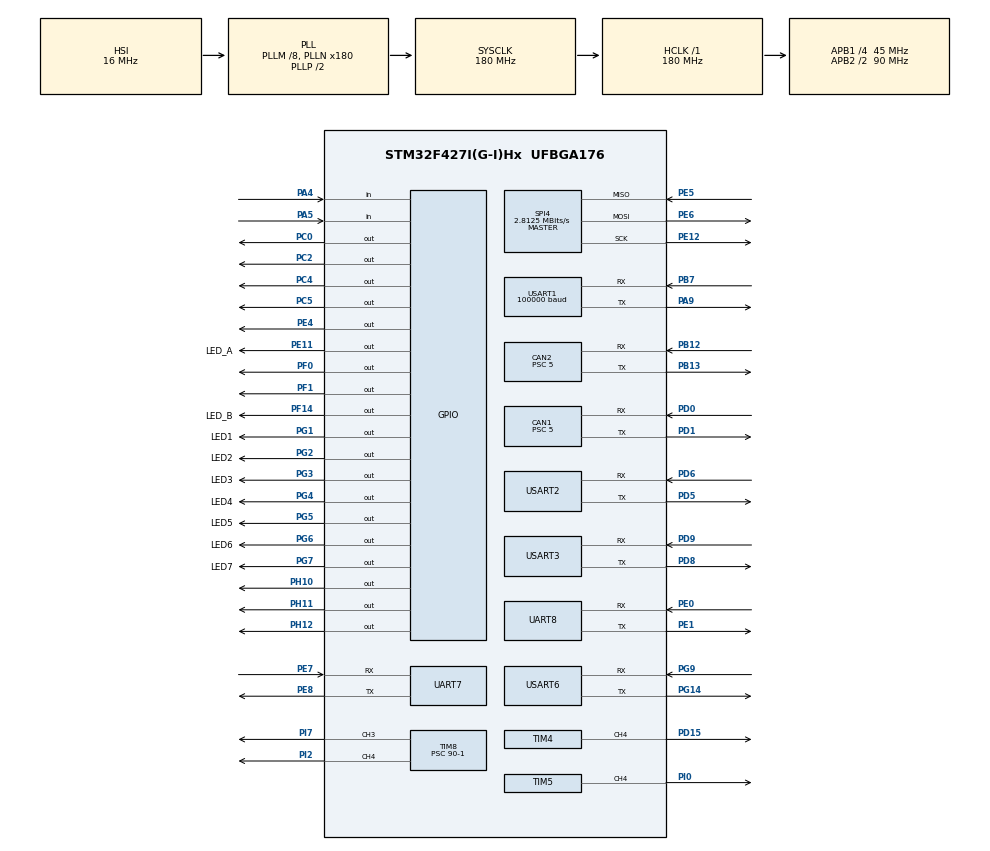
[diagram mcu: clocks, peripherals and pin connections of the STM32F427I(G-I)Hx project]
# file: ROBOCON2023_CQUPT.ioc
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CAN1.ABOM=ENABLE
CAN1.BS1=CAN_BS1_3TQ
CAN1.BS2=CAN_BS2_5TQ
CAN1.CalculateBaudRate=1000000
CAN1.CalculateTimeBit=1000
CAN1.CalculateTimeQuantum=111.11111111111111
CAN1.Prescaler=5
CAN2.ABOM=ENABLE
CAN2.BS1=CAN_BS1_3TQ
CAN2.BS2=CAN_BS2_5TQ
CAN2.CalculateBaudRate=1000000
CAN2.CalculateTimeBit=1000
CAN2.CalculateTimeQuantum=111.11111111111111
CAN2.Prescaler=5
Dma.Request0=USART2_RX
Dma.Request1=USART1_RX
Dma.USART1_RX.1.Direction=DMA_PERIPH_TO_MEMORY
Dma.USART1_RX.1.FIFOMode=DMA_FIFOMODE_DISABLE
Dma.USART1_RX.1.Instance=DMA2_Stream2
Dma.USART1_RX.1.MemDataAlignment=DMA_MDATAALIGN_BYTE
Dma.USART1_RX.1.MemInc=DMA_MINC_ENABLE
Dma.USART1_RX.1.Mode=DMA_CIRCULAR
Dma.USART1_RX.1.PeriphDataAlignment=DMA_PDATAALIGN_BYTE
Dma.USART1_RX.1.PeriphInc=DMA_PINC_DISABLE
Dma.USART1_RX.1.Priority=DMA_PRIORITY_MEDIUM
Dma.USART2_RX.0.Direction=DMA_PERIPH_TO_MEMORY
Dma.USART2_RX.0.FIFOMode=DMA_FIFOMODE_DISABLE
Dma.USART2_RX.0.Instance=DMA1_Stream5
Dma.USART2_RX.0.MemDataAlignment=DMA_MDATAALIGN_BYTE
Dma.USART2_RX.0.MemInc=DMA_MINC_ENABLE
Dma.USART2_RX.0.Mode=DMA_CIRCULAR
Dma.USART2_RX.0.PeriphDataAlignment=DMA_PDATAALIGN_BYTE
Dma.USART2_RX.0.PeriphInc=DMA_PINC_DISABLE
Dma.USART2_RX.0.Priority=DMA_PRIORITY_MEDIUM
FREERTOS.Tasks01=testTask,16,128,test_task,As weak,NULL,Dynamic,NULL,NULL;chassisTask,24,128,chassis_task,As weak,NULL,Dynamic,NULL,NULL;ledTask,8,128,led_task,As weak,NULL,Dynamic,NULL,NULL;solenoidTask,24,128,solenoid_task,As weak,NULL,Dynamic,NULL,NULL;YuntaiTask,24,128,yuntaiTask,As weak,NULL,Dynamic,NULL,NULL
FREERTOS.configENABLE_FPU=1
Mcu.Family=STM32F4
Mcu.Name=STM32F427I(G-I)Hx
Mcu.Package=UFBGA176
NVIC.CAN1_RX0_IRQn=true\:5\:0\:false\:false\:true\:true\:true\:true\:true
NVIC.CAN1_TX_IRQn=true\:5\:0\:false\:false\:true\:true\:true\:true\:true
NVIC.CAN2_RX0_IRQn=true\:5\:0\:false\:false\:true\:true\:true\:true\:true
NVIC.CAN2_TX_IRQn=true\:5\:0\:false\:false\:true\:true\:true\:true\:true
NVIC.DMA1_Stream5_IRQn=true\:5\:0\:false\:false\:true\:true\:false\:true\:true
NVIC.DMA2_Stream2_IRQn=true\:5\:0\:false\:false\:true\:true\:false\:true\:true
NVIC.PriorityGroup=NVIC_PRIORITYGROUP_4
NVIC.TIM2_IRQn=true\:5\:0\:false\:false\:true\:true\:true\:true\:true
NVIC.TIM8_TRG_COM_TIM14_IRQn=true\:5\:0\:false\:false\:true\:false\:false\:true\:true
NVIC.TimeBase=TIM8_TRG_COM_TIM14_IRQn
NVIC.TimeBaseIP=TIM14
NVIC.UART7_IRQn=true\:5\:0\:false\:false\:true\:true\:true\:true\:true
NVIC.UART8_IRQn=true\:5\:0\:false\:false\:true\:true\:true\:true\:true
NVIC.USART1_IRQn=true\:7\:0\:true\:false\:true\:true\:true\:true\:true
NVIC.USART2_IRQn=true\:7\:0\:true\:false\:true\:true\:true\:true\:true
NVIC.USART6_IRQn=true\:6\:0\:true\:false\:true\:true\:true\:true\:true
PA13.Mode=Serial_Wire
PA13.Signal=SYS_JTMS-SWDIO
PA14.Mode=Serial_Wire
PA14.Signal=SYS_JTCK-SWCLK
PA4.GPIO_PuPd=GPIO_PULLDOWN
PA4.Signal=GPIO_Input
PA5.GPIO_PuPd=GPIO_PULLDOWN
PA5.Signal=GPIO_Input
PA9.Mode=Asynchronous
PA9.Signal=USART1_TX
PB12.Mode=CAN_Activate
PB12.Signal=CAN2_RX
PB13.Mode=CAN_Activate
PB13.Signal=CAN2_TX
PB7.Mode=Asynchronous
PB7.Signal=USART1_RX
PC0.Signal=GPIO_Output
PC2.GPIO_PuPd=GPIO_PULLDOWN
PC2.Signal=GPIO_Output
PC4.Signal=GPIO_Output
PC5.Signal=GPIO_Output
PD0.Mode=CAN_Activate
PD0.Signal=CAN1_RX
PD1.Mode=CAN_Activate
PD1.Signal=CAN1_TX
PD15.Signal=S_TIM4_CH4
PD5.Mode=Asynchronous
PD5.Signal=USART2_TX
PD6.Mode=Asynchronous
PD6.Signal=USART2_RX
PD8.Mode=Asynchronous
PD8.Signal=USART3_TX
PD9.Mode=Asynchronous
PD9.Signal=USART3_RX
PE0.Mode=Asynchronous
PE0.Signal=UART8_RX
PE1.Mode=Asynchronous
PE1.Signal=UART8_TX
PE11.GPIO_Label=LED_A
PE11.GPIO_PuPd=GPIO_PULLDOWN
PE11.Signal=GPIO_Output
PE12.Mode=Full_Duplex_Master
PE12.Signal=SPI4_SCK
PE4.GPIO_PuPd=GPIO_PULLDOWN
PE4.Signal=GPIO_Output
PE5.Mode=Full_Duplex_Master
PE5.Signal=SPI4_MISO
PE6.Mode=Full_Duplex_Master
PE6.Signal=SPI4_MOSI
PE7.Mode=Asynchronous
PE7.Signal=UART7_RX
PE8.Mode=Asynchronous
PE8.Signal=UART7_TX
PF0.GPIO_PuPd=GPIO_PULLDOWN
PF0.Signal=GPIO_Output
PF1.GPIO_PuPd=GPIO_PULLDOWN
PF1.PinState=GPIO_PIN_RESET
PF1.Signal=GPIO_Output
PF14.GPIO_Label=LED_B
PF14.GPIO_PuPd=GPIO_PULLDOWN
PF14.Signal=GPIO_Output
PG1.GPIO_Label=LED1
PG1.GPIO_PuPd=GPIO_PULLDOWN
PG1.Signal=GPIO_Output
PG14.Mode=Asynchronous
PG14.Signal=USART6_TX
PG2.GPIO_Label=LED2
PG2.GPIO_PuPd=GPIO_PULLDOWN
PG2.Signal=GPIO_Output
PG3.GPIO_Label=LED3
PG3.GPIO_PuPd=GPIO_PULLDOWN
PG3.Signal=GPIO_Output
PG4.GPIO_Label=LED4
PG4.GPIO_PuPd=GPIO_PULLDOWN
PG4.Signal=GPIO_Output
PG5.GPIO_Label=LED5
PG5.GPIO_PuPd=GPIO_PULLDOWN
PG5.Signal=GPIO_Output
PG6.GPIO_Label=LED6
PG6.GPIO_PuPd=GPIO_PULLDOWN
PG6.Signal=GPIO_Output
PG7.GPIO_Label=LED7
PG7.GPIO_PuPd=GPIO_PULLDOWN
PG7.Signal=GPIO_Output
PG9.Mode=Asynchronous
PG9.Signal=USART6_RX
PH0/OSC_IN.Mode=HSE-External-Oscillator
PH0/OSC_IN.Signal=RCC_OSC_IN
PH1/OSC_OUT.Mode=HSE-External-Oscillator
PH1/OSC_OUT.Signal=RCC_OSC_OUT
PH10.PinState=GPIO_PIN_SET
PH10.Signal=GPIO_Output
PH11.PinState=GPIO_PIN_SET
PH11.Signal=GPIO_Output
PH12.PinState=GPIO_PIN_SET
PH12.Signal=GPIO_Output
PI0.Signal=S_TIM5_CH4
PI2.Signal=S_TIM8_CH4
PI7.Signal=S_TIM8_CH3
ProjectManager.HeapSize=0x800
ProjectManager.StackSize=0x1200
ProjectManager.TargetToolchain=MDK-ARM V5.32
RCC.48MHZClocksFreq_Value=90000000
RCC.AHBFreq_Value=180000000
RCC.APB1CLKDivider=RCC_HCLK_DIV4
RCC.APB1Freq_Value=45000000
RCC.APB1TimFreq_Value=90000000
RCC.APB2CLKDivider=RCC_HCLK_DIV2
RCC.APB2Freq_Value=90000000
RCC.APB2TimFreq_Value=180000000
RCC.CortexFreq_Value=180000000
RCC.HCLKFreq_Value=180000000
RCC.HSE_VALUE=25000000
RCC.HSI_VALUE=16000000
RCC.LSE_VALUE=32768
RCC.PLLM=8
RCC.PLLN=180
RCC.SYSCLKFreq_VALUE=180000000
RCC.SYSCLKSource=RCC_SYSCLKSOURCE_PLLCLK
RCC.VCOOutputFreq_Value=360000000
SH.S_TIM4_CH4.0=TIM4_CH4,PWM Generation4 CH4
SH.S_TIM5_CH4.0=TIM5_CH4,PWM Generation4 CH4
SH.S_TIM8_CH3.0=TIM8_CH3,PWM Generation3 CH3
SH.S_TIM8_CH4.0=TIM8_CH4,PWM Generation4 CH4
SPI4.BaudRatePrescaler=SPI_BAUDRATEPRESCALER_32
SPI4.CLKPhase=SPI_PHASE_2EDGE
SPI4.CalculateBaudRate=2.8125 MBits/s
SPI4.DataSize=SPI_DATASIZE_16BIT
SPI4.Direction=SPI_DIRECTION_2LINES
SPI4.Mode=SPI_MODE_MASTER
SPI4.VirtualType=VM_MASTER
TIM2.Period=1000000-1
TIM2.Prescaler=180-1
TIM4.AutoReloadPreload=TIM_AUTORELOAD_PRELOAD_ENABLE
TIM4.Channel-PWM\ Generation4\ CH4=TIM_CHANNEL_4
TIM4.Period=10000-1
TIM4.Prescaler=90-1
TIM5.Channel-PWM\ Generation4\ CH4=TIM_CHANNEL_4
TIM5.Period=10000
TIM5.Prescaler=169
TIM8.AutoReloadPreload=TIM_AUTORELOAD_PRELOAD_ENABLE
TIM8.Channel-PWM\ Generation3\ CH3=TIM_CHANNEL_3
TIM8.Channel-PWM\ Generation4\ CH4=TIM_CHANNEL_4
TIM8.Period=40000-1
TIM8.Prescaler=90-1
UART7.VirtualMode=Asynchronous
UART8.VirtualMode=Asynchronous
USART1.BaudRate=100000
USART1.VirtualMode=VM_ASYNC
USART2.VirtualMode=VM_ASYNC
USART3.VirtualMode=VM_ASYNC
USART6.VirtualMode=VM_ASYNC
VP_FREERTOS_VS_CMSIS_V2.Mode=CMSIS_V2
VP_SYS_VS_tim14.Mode=TIM14
VP_TIM2_VS_ClockSourceINT.Mode=Internal
VP_TIM4_VS_ClockSourceINT.Mode=Internal
VP_TIM8_VS_ClockSourceINT.Mode=Internal
board=custom

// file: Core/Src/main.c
/* USER CODE BEGIN Header */
/**
  ******************************************************************************
  * @file           : main.c
  * @brief          : Main program body
  ******************************************************************************
  * @attention
  *
  * Copyright (c) 2023 STMicroelectronics.
  * All rights reserved.
  *
  * This software is licensed under terms that can be found in the LICENSE file
  * in the root directory of this software component.
  * If no LICENSE file comes with this software, it is provided AS-IS.
  *
  ******************************************************************************
  */
/* USER CODE END Header */
#include "main.h"
#include "cmsis_os.h"
#include "can.h"
#include "dma.h"
#include "spi.h"
#include "tim.h"
#include "usart.h"
#include "gpio.h"

/* USER CODE BEGIN Includes */
#include "dj_m2006_3508_driver.h"
/* USER CODE END Includes */

void SystemClock_Config(void);
void MX_FREERTOS_Init(void);

int main(void)
{

  /* MCU Configuration--------------------------------------------------------*/

  /* Reset of all peripherals, Initializes the Flash interface and the Systick. */
  HAL_Init();

  /* Configure the system clock */
  SystemClock_Config();

  /* Initialize all configured peripherals */
  MX_GPIO_Init();
  MX_DMA_Init();
  MX_CAN1_Init();
  MX_CAN2_Init();
  MX_SPI4_Init();
  MX_USART1_UART_Init();
  MX_USART2_UART_Init();
  MX_USART3_UART_Init();
  MX_USART6_UART_Init();
  MX_UART7_Init();
  MX_UART8_Init();
  MX_TIM4_Init();
  MX_TIM8_Init();
  MX_TIM2_Init();
  MX_TIM5_Init();
  /* USER CODE BEGIN 2 */
 userShellInit();
 dj_motor_init();
 HAL_TIM_PWM_Start(&htim5,TIM_CHANNEL_4);
  /* USER CODE END 2 */

  /* Init scheduler */
  osKernelInitialize();  /* Call init function for freertos objects (in freertos.c) */
  MX_FREERTOS_Init();

  /* Start scheduler */
  osKernelStart();
  /* We should never get here as control is now taken by the scheduler */
  /* Infinite loop */
  while (1)
  {

  }
}

void SystemClock_Config(void)
{
  RCC_OscInitTypeDef RCC_OscInitStruct = {0};
  RCC_ClkInitTypeDef RCC_ClkInitStruct = {0};

  /** Configure the main internal regulator output voltage
  */
  __HAL_RCC_PWR_CLK_ENABLE();
  __HAL_PWR_VOLTAGESCALING_CONFIG(PWR_REGULATOR_VOLTAGE_SCALE1);

  /** Initializes the RCC Oscillators according to the specified parameters
  * in the RCC_OscInitTypeDef structure.
  */
  RCC_OscInitStruct.OscillatorType = RCC_OSCILLATORTYPE_HSI;
  RCC_OscInitStruct.HSIState = RCC_HSI_ON;
  RCC_OscInitStruct.HSICalibrationValue = RCC_HSICALIBRATION_DEFAULT;
  RCC_OscInitStruct.PLL.PLLState = RCC_PLL_ON;
  RCC_OscInitStruct.PLL.PLLSource = RCC_PLLSOURCE_HSI;
  RCC_OscInitStruct.PLL.PLLM = 8;
  RCC_OscInitStruct.PLL.PLLN = 180;
  RCC_OscInitStruct.PLL.PLLP = RCC_PLLP_DIV2;
  RCC_OscInitStruct.PLL.PLLQ = 4;
  if (HAL_RCC_OscConfig(&RCC_OscInitStruct) != HAL_OK)
  {
    Error_Handler();
  }

  /** Activate the Over-Drive mode
  */
  if (HAL_PWREx_EnableOverDrive() != HAL_OK)
  {
    Error_Handler();
  }

  /** Initializes the CPU, AHB and APB buses clocks
  */
  RCC_ClkInitStruct.ClockType = RCC_CLOCKTYPE_HCLK|RCC_CLOCKTYPE_SYSCLK
                              |RCC_CLOCKTYPE_PCLK1|RCC_CLOCKTYPE_PCLK2;
  RCC_ClkInitStruct.SYSCLKSource = RCC_SYSCLKSOURCE_PLLCLK;
  RCC_ClkInitStruct.AHBCLKDivider = RCC_SYSCLK_DIV1;
  RCC_ClkInitStruct.APB1CLKDivider = RCC_HCLK_DIV4;
  RCC_ClkInitStruct.APB2CLKDivider = RCC_HCLK_DIV2;

  if (HAL_RCC_ClockConfig(&RCC_ClkInitStruct, FLASH_LATENCY_5) != HAL_OK)
  {
    Error_Handler();
  }
}

void HAL_TIM_PeriodElapsedCallback(TIM_HandleTypeDef *htim)
{
  if (htim->Instance == TIM14) {
    HAL_IncTick();
  }
}

void Error_Handler(void)
{
  __disable_irq();
  while (1)
  {
  }
}

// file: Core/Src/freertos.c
/* USER CODE BEGIN Header */
/**
  ******************************************************************************
  * File Name          : freertos.c
  * Description        : Code for freertos applications
  ******************************************************************************
  * @attention
  *
  * Copyright (c) 2023 STMicroelectronics.
  * All rights reserved.
  *
  * This software is licensed under terms that can be found in the LICENSE file
  * in the root directory of this software component.
  * If no LICENSE file comes with this software, it is provided AS-IS.
  *
  ******************************************************************************
  */
/* USER CODE END Header */

#include "FreeRTOS.h"
#include "task.h"
#include "main.h"
#include "cmsis_os.h"

/* USER CODE BEGIN Includes */
#include "semphr.h"
/* USER CODE END Includes */

/* USER CODE BEGIN Variables */
SemaphoreHandle_t xMutex_Usart1;

/* USER CODE END Variables */
/* Definitions for testTask */
osThreadId_t testTaskHandle;
const osThreadAttr_t testTask_attributes = {
  .name = "testTask",
  .stack_size = 128 * 4,
  .priority = (osPriority_t) osPriorityBelowNormal,
};
/* Definitions for chassisTask */
osThreadId_t chassisTaskHandle;
const osThreadAttr_t chassisTask_attributes = {
  .name = "chassisTask",
  .stack_size = 128 * 4,
  .priority = (osPriority_t) osPriorityNormal,
};
/* Definitions for ledTask */
osThreadId_t ledTaskHandle;
const osThreadAttr_t ledTask_attributes = {
  .name = "ledTask",
  .stack_size = 128 * 4,
  .priority = (osPriority_t) osPriorityLow,
};
/* Definitions for solenoidTask */
osThreadId_t solenoidTaskHandle;
const osThreadAttr_t solenoidTask_attributes = {
  .name = "solenoidTask",
  .stack_size = 128 * 4,
  .priority = (osPriority_t) osPriorityNormal,
};
/* Definitions for YuntaiTask */
osThreadId_t YuntaiTaskHandle;
const osThreadAttr_t YuntaiTask_attributes = {
  .name = "YuntaiTask",
  .stack_size = 128 * 4,
  .priority = (osPriority_t) osPriorityNormal,
};

void test_task(void *argument);
void chassis_task(void *argument);
void led_task(void *argument);
void solenoid_task(void *argument);
void yuntaiTask(void *argument);

void MX_FREERTOS_Init(void); /* (MISRA C 2004 rule 8.1) */

void MX_FREERTOS_Init(void) {

  /* USER CODE BEGIN RTOS_MUTEX */
	    xMutex_Usart1 = xSemaphoreCreateRecursiveMutex();

  /* USER CODE END RTOS_MUTEX */

  /* Create the thread(s) */
  /* creation of testTask */
  testTaskHandle = osThreadNew(test_task, NULL, &testTask_attributes);

  /* creation of chassisTask */
  chassisTaskHandle = osThreadNew(chassis_task, NULL, &chassisTask_attributes);

  /* creation of ledTask */
  ledTaskHandle = osThreadNew(led_task, NULL, &ledTask_attributes);

  /* creation of solenoidTask */
  solenoidTaskHandle = osThreadNew(solenoid_task, NULL, &solenoidTask_attributes);

  /* creation of YuntaiTask */
  YuntaiTaskHandle = osThreadNew(yuntaiTask, NULL, &YuntaiTask_attributes);

}

__weak void test_task(void *argument)
{
  for(;;)
  {
    osDelay(1);
  }
}

__weak void chassis_task(void *argument)
{
  for(;;)
  {
    osDelay(1);
  }
}

__weak void led_task(void *argument)
{
  for(;;)
  {
    osDelay(1);
  }
}

__weak void solenoid_task(void *argument)
{
  for(;;)
  {
    osDelay(1);
  }
}

__weak void yuntaiTask(void *argument)
{
  for(;;)
  {
    osDelay(1);
  }
}
